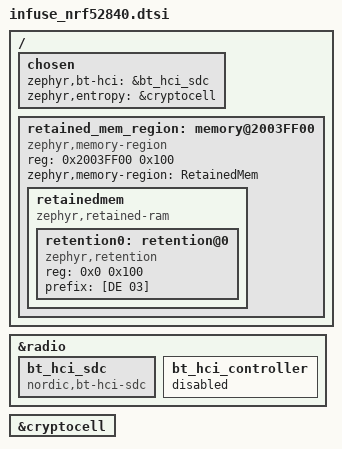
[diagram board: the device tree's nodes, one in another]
/ {
	chosen {
		zephyr,bt-hci = &bt_hci_sdc;
	};

	/* End of application SRAM */
	retained_mem_region: memory@2003FF00 {
		compatible = "zephyr,memory-region", "mmio-sram";
		reg = <0x2003FF00 0x100>;
		zephyr,memory-region = "RetainedMem";
		status = "okay";

		retainedmem {
			compatible = "zephyr,retained-ram";
			status = "okay";
			#address-cells = <1>;
			#size-cells = <1>;

			retention0: retention@0 {
					compatible = "zephyr,retention";
					status = "okay";
					reg = <0x0 0x100>;
					prefix = [DE 03];
			};
		};
	};
};

&radio {
	bt_hci_sdc: bt_hci_sdc {
		compatible = "nordic,bt-hci-sdc";
		status = "okay";
	};
	bt_hci_controller {
		status = "disabled";
	};
};

#ifndef INFUSE_IS_BOOTLOADER

/ {
	chosen {
		zephyr,entropy = &cryptocell;
	};
};

/* Bootloader shouldn't be using cryptocell */
&cryptocell {
	status = "okay";
};

#endif /* !INFUSE_IS_BOOTLOADER */
